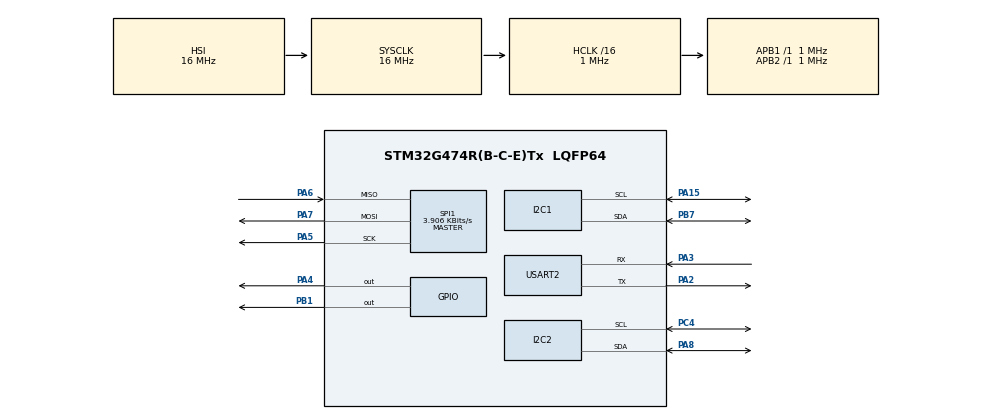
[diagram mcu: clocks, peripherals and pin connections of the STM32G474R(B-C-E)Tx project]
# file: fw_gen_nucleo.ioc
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I2C1.Timing=0x00000103
I2C2.Timing=0x00000103
Mcu.Family=STM32G4
Mcu.Name=STM32G474R(B-C-E)Tx
Mcu.Package=LQFP64
NVIC.PriorityGroup=NVIC_PRIORITYGROUP_4
PA13.GPIO_Label=T_SWDIO
PA13.Signal=SYS_JTMS-SWDIO
PA14.GPIO_Label=T_SWCLK
PA14.Signal=SYS_JTCK-SWCLK
PA15.Mode=I2C
PA15.Signal=I2C1_SCL
PA2.Mode=Asynchronous
PA2.Signal=USART2_TX
PA3.Mode=Asynchronous
PA3.Signal=USART2_RX
PA4.Signal=GPIO_Output
PA5.Mode=Full_Duplex_Master
PA5.Signal=SPI1_SCK
PA6.Mode=Full_Duplex_Master
PA6.Signal=SPI1_MISO
PA7.Mode=Full_Duplex_Master
PA7.Signal=SPI1_MOSI
PA8.Mode=I2C
PA8.Signal=I2C2_SDA
PB1.GPIO_PuPd=GPIO_PULLUP
PB1.PinState=GPIO_PIN_SET
PB1.Signal=GPIO_Output
PB3.GPIO_Label=T_SWO
PB3.Signal=SYS_JTDO-SWO
PB7.Mode=I2C
PB7.Signal=I2C1_SDA
PC14-OSC32_IN.GPIO_Label=RCC_OSC32_IN
PC14-OSC32_IN.Signal=RCC_OSC32_IN
PC15-OSC32_OUT.GPIO_Label=RCC_OSC32_OUT
PC15-OSC32_OUT.Signal=RCC_OSC32_OUT
PC4.Mode=I2C
PC4.Signal=I2C2_SCL
PF0-OSC_IN.GPIO_Label=RCC_OSC_IN
PF0-OSC_IN.Signal=RCC_OSC_IN
PF1-OSC_OUT.GPIO_Label=RCC_OSC_OUT
PF1-OSC_OUT.Signal=RCC_OSC_OUT
ProjectManager.HeapSize=0x200
ProjectManager.StackSize=0x400
ProjectManager.TargetToolchain=CMake
RCC.ADC12Freq_Value=16000000
RCC.ADC345Freq_Value=16000000
RCC.AHBCLKDivider=RCC_SYSCLK_DIV16
RCC.AHBFreq_Value=1000000
RCC.APB1Freq_Value=1000000
RCC.APB1TimFreq_Value=1000000
RCC.APB2Freq_Value=1000000
RCC.APB2TimFreq_Value=1000000
RCC.CortexFreq_Value=1000000
RCC.EXTERNAL_CLOCK_VALUE=12288000
RCC.HCLKFreq_Value=1000000
RCC.HSE_VALUE=24000000
RCC.HSI48_VALUE=48000000
RCC.HSI_VALUE=16000000
RCC.PLLN=12
RCC.PLLQ=RCC_PLLQ_DIV4
RCC.RTCClockSelection=RCC_RTCCLKSOURCE_LSE
RCC.SYSCLKFreq_VALUE=16000000
RCC.USBFreq_Value=48000000
RCC.VCOOutputFreq_Value=192000000
SPI1.BaudRatePrescaler=SPI_BAUDRATEPRESCALER_256
SPI1.CalculateBaudRate=3.906 KBits/s
SPI1.DataSize=SPI_DATASIZE_8BIT
SPI1.Direction=SPI_DIRECTION_2LINES
SPI1.Mode=SPI_MODE_MASTER
SPI1.VirtualType=VM_MASTER
USART2.VirtualMode-Asynchronous=VM_ASYNC
VP_SYS_VS_DBSignals.Mode=DisableDeadBatterySignals
board=NUCLEO-G474RE

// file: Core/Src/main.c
/* USER CODE BEGIN Header */
/**
  ******************************************************************************
  * @file           : main.c
  * @brief          : Main program body
  ******************************************************************************
  * @attention
  *
  * Copyright (c) 2026 STMicroelectronics.
  * All rights reserved.
  *
  * This software is licensed under terms that can be found in the LICENSE file
  * in the root directory of this software component.
  * If no LICENSE file comes with this software, it is provided AS-IS.
  *
  ******************************************************************************
  */
/* USER CODE END Header */
#include "main.h"
#include "i2c.h"
#include "spi.h"
#include "usart.h"
#include "gpio.h"

void SystemClock_Config(void);

int main(void)
{

  /* MCU Configuration--------------------------------------------------------*/

  /* Reset of all peripherals, Initializes the Flash interface and the Systick. */
  HAL_Init();

  /* Configure the system clock */
  SystemClock_Config();

  /* Initialize all configured peripherals */
  MX_GPIO_Init();
  MX_I2C1_Init();
  MX_USART2_UART_Init();
  MX_SPI1_Init();
  MX_I2C2_Init();

  /* Infinite loop */
  /* USER CODE BEGIN WHILE */
  while (1)
  {

    /* -- Sample board code for User push-button in interrupt mode ---- */
    if (BspButtonState == BUTTON_PRESSED)
    {
      /* Update button state */
      BspButtonState = BUTTON_RELEASED;
      /* -- Sample board code to toggle led ---- */
      BSP_LED_Toggle(LED_GREEN);

      /* ..... Perform your action ..... */
    }
    /* USER CODE END WHILE */

  }
}

void SystemClock_Config(void)
{
  RCC_OscInitTypeDef RCC_OscInitStruct = {0};
  RCC_ClkInitTypeDef RCC_ClkInitStruct = {0};

  /** Configure the main internal regulator output voltage
  */
  HAL_PWREx_ControlVoltageScaling(PWR_REGULATOR_VOLTAGE_SCALE1);

  /** Initializes the RCC Oscillators according to the specified parameters
  * in the RCC_OscInitTypeDef structure.
  */
  RCC_OscInitStruct.OscillatorType = RCC_OSCILLATORTYPE_HSI;
  RCC_OscInitStruct.HSIState = RCC_HSI_ON;
  RCC_OscInitStruct.HSICalibrationValue = RCC_HSICALIBRATION_DEFAULT;
  RCC_OscInitStruct.PLL.PLLState = RCC_PLL_NONE;
  if (HAL_RCC_OscConfig(&RCC_OscInitStruct) != HAL_OK)
  {
    Error_Handler();
  }

  /** Initializes the CPU, AHB and APB buses clocks
  */
  RCC_ClkInitStruct.ClockType = RCC_CLOCKTYPE_HCLK|RCC_CLOCKTYPE_SYSCLK
                              |RCC_CLOCKTYPE_PCLK1|RCC_CLOCKTYPE_PCLK2;
  RCC_ClkInitStruct.SYSCLKSource = RCC_SYSCLKSOURCE_HSI;
  RCC_ClkInitStruct.AHBCLKDivider = RCC_SYSCLK_DIV16;
  RCC_ClkInitStruct.APB1CLKDivider = RCC_HCLK_DIV1;
  RCC_ClkInitStruct.APB2CLKDivider = RCC_HCLK_DIV1;

  if (HAL_RCC_ClockConfig(&RCC_ClkInitStruct, FLASH_LATENCY_0) != HAL_OK)
  {
    Error_Handler();
  }
}

void Error_Handler(void)
{
  __disable_irq();
  while (1)
  {
  }
}
